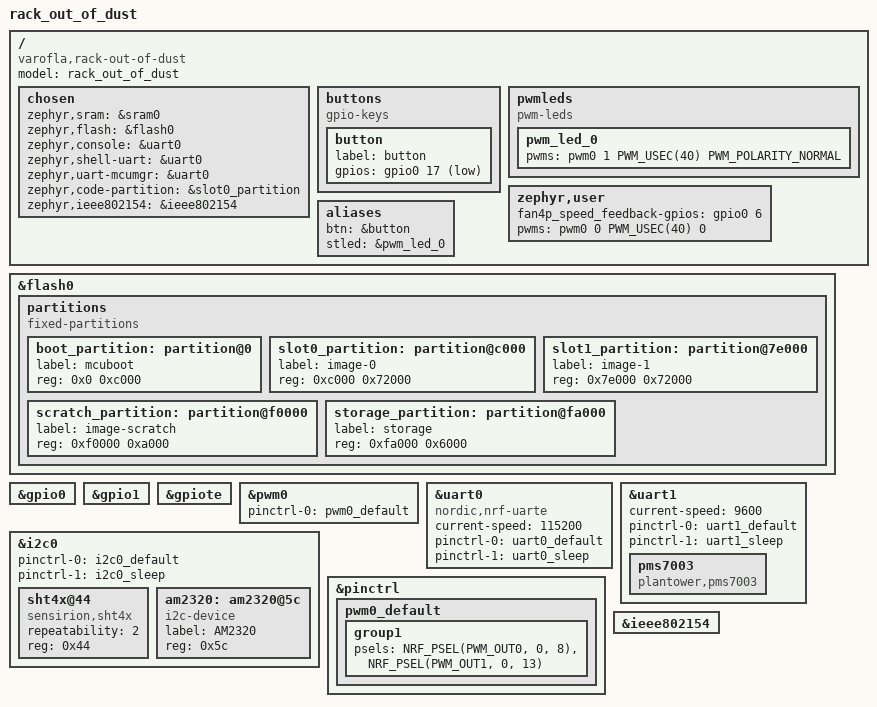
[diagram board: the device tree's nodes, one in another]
/dts-v1/;
#include <nordic/nrf52840_qiaa.dtsi>
#include "rack_out_of_dust.dtsi"

/ {
	model = "rack_out_of_dust";
	compatible = "varofla,rack-out-of-dust";

	chosen {
		zephyr,sram = &sram0;
		zephyr,flash = &flash0;
		zephyr,console = &uart0;
		zephyr,shell-uart = &uart0;
		zephyr,uart-mcumgr = &uart0;

		zephyr,code-partition = &slot0_partition;
		zephyr,ieee802154 = &ieee802154;
	};

	buttons {
		compatible = "gpio-keys";
		button: button {
			label = "button";
			gpios = <&gpio0 17 GPIO_ACTIVE_LOW>;
		};
	};

	pwmleds {
		compatible = "pwm-leds";
		pwm_led_0: pwm_led_0 {
			pwms = <&pwm0 1 PWM_USEC(40) PWM_POLARITY_NORMAL>;
		};
	};

	zephyr,user {
		fan4p_speed_feedback-gpios = <&gpio0 6 0>;
		pwms = <&pwm0 0 PWM_USEC(40) 0>;
	};

	aliases {
		btn = &button;
		stled = &pwm_led_0;
	};
};

&flash0 {
	partitions {
		compatible = "fixed-partitions";
		#address-cells = <1>;
		#size-cells = <1>;

		boot_partition: partition@0 {
			label = "mcuboot";
			reg = <0x0 0xc000>;
		};
		slot0_partition: partition@c000 {
			label = "image-0";
			reg = <0xc000 0x72000>;
		};
		slot1_partition: partition@7e000 {
			label = "image-1";
			reg = <0x7e000 0x72000>;
		};
		scratch_partition: partition@f0000 {
			label = "image-scratch";
			reg = <0xf0000 0xa000>;
		};
		storage_partition: partition@fa000 {
			label = "storage";
			reg = <0xfa000 0x6000>;
		};
	};
};

&gpio0 {
	status = "okay";
};

&gpio1 {
	status = "okay";
};

&gpiote {
	status = "okay";
};

&pwm0 {
	status = "okay";
	pinctrl-0 = <&pwm0_default>;
	pinctrl-names = "default";
};

&uart0 {
	compatible = "nordic,nrf-uarte";
	status = "okay";
	current-speed = <115200>;
	pinctrl-0 = <&uart0_default>;
	pinctrl-1 = <&uart0_sleep>;
	pinctrl-names = "default", "sleep";
};

&uart1 {
	status = "okay";
	current-speed = <9600>;
	pinctrl-0 = <&uart1_default>;
	pinctrl-1 = <&uart1_sleep>;
	pinctrl-names = "default", "sleep";
	pms7003 {
		compatible = "plantower,pms7003";
	};
};

&i2c0 {
	status = "okay";
	pinctrl-0 = <&i2c0_default>;
	pinctrl-1 = <&i2c0_sleep>;
	pinctrl-names = "default", "sleep";
	sht4x@44 {
		compatible = "sensirion,sht4x";
		repeatability = <2>;
		reg = <0x44>;
	};
	am2320: am2320@5c {
		compatible = "i2c-device";
		status = "okay";
		label = "AM2320";
		reg = <0x5c>;
	};
};

&pinctrl {
	pwm0_default: pwm0_default {
		group1 {
			psels = <NRF_PSEL(PWM_OUT0, 0, 8)>, <NRF_PSEL(PWM_OUT1, 0, 13)>;
		};
	};
};

&ieee802154 {
	status = "okay";
};
